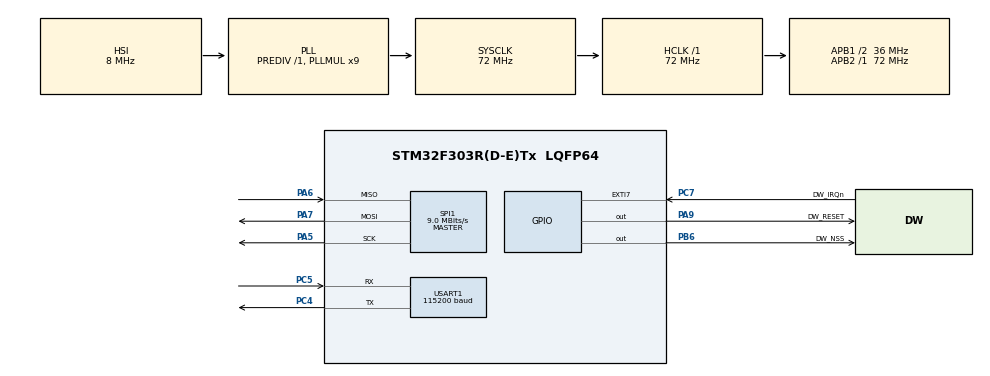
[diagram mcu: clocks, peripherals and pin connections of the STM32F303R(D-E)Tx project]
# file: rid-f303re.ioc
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Mcu.Family=STM32F3
Mcu.Name=STM32F303R(D-E)Tx
Mcu.Package=LQFP64
NVIC.PriorityGroup=NVIC_PRIORITYGROUP_4
PA13.Mode=Serial_Wire
PA13.Signal=SYS_JTMS-SWDIO
PA14.Mode=Serial_Wire
PA14.Signal=SYS_JTCK-SWCLK
PA5.Mode=Full_Duplex_Master
PA5.Signal=SPI1_SCK
PA6.Mode=Full_Duplex_Master
PA6.Signal=SPI1_MISO
PA7.Mode=Full_Duplex_Master
PA7.Signal=SPI1_MOSI
PA9.GPIO_Label=DW_RESET
PA9.Signal=GPIO_Output
PB6.GPIO_Label=DW_NSS
PB6.PinState=GPIO_PIN_SET
PB6.Signal=GPIO_Output
PC4.Mode=Asynchronous
PC4.Signal=USART1_TX
PC5.Mode=Asynchronous
PC5.Signal=USART1_RX
PC7.GPIO_Label=DW_IRQn
PC7.GPIO_PuPd=GPIO_PULLDOWN
PC7.Signal=GPXTI7
ProjectManager.HeapSize=0x200
ProjectManager.StackSize=0x400
ProjectManager.TargetToolchain=STM32CubeIDE
RCC.AHBFreq_Value=72000000
RCC.APB1CLKDivider=RCC_HCLK_DIV2
RCC.APB1Freq_Value=36000000
RCC.APB1TimFreq_Value=72000000
RCC.APB2Freq_Value=72000000
RCC.APB2TimFreq_Value=72000000
RCC.CortexFreq_Value=72000000
RCC.HCLKFreq_Value=72000000
RCC.HSE_VALUE=8000000
RCC.HSI_VALUE=8000000
RCC.LSE_VALUE=32768
RCC.PLLMUL=RCC_PLL_MUL9
RCC.SYSCLKFreq_VALUE=72000000
RCC.SYSCLKSourceVirtual=RCC_SYSCLKSOURCE_PLLCLK
RCC.USBFreq_Value=72000000
SPI1.BaudRatePrescaler=SPI_BAUDRATEPRESCALER_8
SPI1.CalculateBaudRate=9.0 MBits/s
SPI1.DataSize=SPI_DATASIZE_8BIT
SPI1.Direction=SPI_DIRECTION_2LINES
SPI1.Mode=SPI_MODE_MASTER
SPI1.NSSPMode=SPI_NSS_PULSE_DISABLE
SPI1.VirtualType=VM_MASTER
USART1.BaudRate=115200
USART1.VirtualMode-Asynchronous=VM_ASYNC
board=custom

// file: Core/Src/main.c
/* USER CODE BEGIN Header */
/**
  ******************************************************************************
  * @file           : main.c
  * @brief          : Main program body
  ******************************************************************************
  * @attention
  *
  * Copyright (c) 2022 STMicroelectronics.
  * All rights reserved.
  *
  * This software is licensed under terms that can be found in the LICENSE file
  * in the root directory of this software component.
  * If no LICENSE file comes with this software, it is provided AS-IS.
  *
  ******************************************************************************
  */
/* USER CODE END Header */
#include "main.h"

/* USER CODE BEGIN Includes */
#include "stdio_d.h"
#include "rid.h"

//#include "ex_01a_simple_tx/ex_01a_main.c"
/* USER CODE END Includes */

SPI_HandleTypeDef hspi1;

UART_HandleTypeDef huart1;

void SystemClock_Config(void);
static void MX_GPIO_Init(void);
static void MX_SPI1_Init(void);
static void MX_USART1_UART_Init(void);

int main(void)
{

  /* MCU Configuration--------------------------------------------------------*/

  /* Reset of all peripherals, Initializes the Flash interface and the Systick. */
  HAL_Init();

  /* Configure the system clock */
  SystemClock_Config();

  /* Initialize all configured peripherals */
  MX_GPIO_Init();
  MX_SPI1_Init();
  MX_USART1_UART_Init();
  /* USER CODE BEGIN 2 */
  stdio_init(&huart1);
  rid_main();
  //  dw_main();
  /* USER CODE END 2 */

  /* Infinite loop */
  while (1)
  {

  }
}

void SystemClock_Config(void)
{
  RCC_OscInitTypeDef RCC_OscInitStruct = {0};
  RCC_ClkInitTypeDef RCC_ClkInitStruct = {0};
  RCC_PeriphCLKInitTypeDef PeriphClkInit = {0};

  /** Initializes the RCC Oscillators according to the specified parameters
  * in the RCC_OscInitTypeDef structure.
  */
  RCC_OscInitStruct.OscillatorType = RCC_OSCILLATORTYPE_HSI;
  RCC_OscInitStruct.HSIState = RCC_HSI_ON;
  RCC_OscInitStruct.HSICalibrationValue = RCC_HSICALIBRATION_DEFAULT;
  RCC_OscInitStruct.PLL.PLLState = RCC_PLL_ON;
  RCC_OscInitStruct.PLL.PLLSource = RCC_PLLSOURCE_HSI;
  RCC_OscInitStruct.PLL.PLLMUL = RCC_PLL_MUL9;
  RCC_OscInitStruct.PLL.PREDIV = RCC_PREDIV_DIV1;
  if (HAL_RCC_OscConfig(&RCC_OscInitStruct) != HAL_OK)
  {
    Error_Handler();
  }

  /** Initializes the CPU, AHB and APB buses clocks
  */
  RCC_ClkInitStruct.ClockType = RCC_CLOCKTYPE_HCLK|RCC_CLOCKTYPE_SYSCLK
                              |RCC_CLOCKTYPE_PCLK1|RCC_CLOCKTYPE_PCLK2;
  RCC_ClkInitStruct.SYSCLKSource = RCC_SYSCLKSOURCE_PLLCLK;
  RCC_ClkInitStruct.AHBCLKDivider = RCC_SYSCLK_DIV1;
  RCC_ClkInitStruct.APB1CLKDivider = RCC_HCLK_DIV2;
  RCC_ClkInitStruct.APB2CLKDivider = RCC_HCLK_DIV1;

  if (HAL_RCC_ClockConfig(&RCC_ClkInitStruct, FLASH_LATENCY_2) != HAL_OK)
  {
    Error_Handler();
  }
  PeriphClkInit.PeriphClockSelection = RCC_PERIPHCLK_USART1;
  PeriphClkInit.Usart1ClockSelection = RCC_USART1CLKSOURCE_PCLK2;
  if (HAL_RCCEx_PeriphCLKConfig(&PeriphClkInit) != HAL_OK)
  {
    Error_Handler();
  }
}

static void MX_SPI1_Init(void)
{

  /* SPI1 parameter configuration*/
  hspi1.Instance = SPI1;
  hspi1.Init.Mode = SPI_MODE_MASTER;
  hspi1.Init.Direction = SPI_DIRECTION_2LINES;
  hspi1.Init.DataSize = SPI_DATASIZE_8BIT;
  hspi1.Init.CLKPolarity = SPI_POLARITY_LOW;
  hspi1.Init.CLKPhase = SPI_PHASE_1EDGE;
  hspi1.Init.NSS = SPI_NSS_SOFT;
  hspi1.Init.BaudRatePrescaler = SPI_BAUDRATEPRESCALER_8;
  hspi1.Init.FirstBit = SPI_FIRSTBIT_MSB;
  hspi1.Init.TIMode = SPI_TIMODE_DISABLE;
  hspi1.Init.CRCCalculation = SPI_CRCCALCULATION_DISABLE;
  hspi1.Init.CRCPolynomial = 7;
  hspi1.Init.CRCLength = SPI_CRC_LENGTH_DATASIZE;
  hspi1.Init.NSSPMode = SPI_NSS_PULSE_DISABLE;
  if (HAL_SPI_Init(&hspi1) != HAL_OK)
  {
    Error_Handler();
  }

}

static void MX_USART1_UART_Init(void)
{

  huart1.Instance = USART1;
  huart1.Init.BaudRate = 115200;
  huart1.Init.WordLength = UART_WORDLENGTH_8B;
  huart1.Init.StopBits = UART_STOPBITS_1;
  huart1.Init.Parity = UART_PARITY_NONE;
  huart1.Init.Mode = UART_MODE_TX_RX;
  huart1.Init.HwFlowCtl = UART_HWCONTROL_NONE;
  huart1.Init.OverSampling = UART_OVERSAMPLING_16;
  huart1.Init.OneBitSampling = UART_ONE_BIT_SAMPLE_DISABLE;
  huart1.AdvancedInit.AdvFeatureInit = UART_ADVFEATURE_NO_INIT;
  if (HAL_UART_Init(&huart1) != HAL_OK)
  {
    Error_Handler();
  }

}

static void MX_GPIO_Init(void)
{
  GPIO_InitTypeDef GPIO_InitStruct = {0};

  /* GPIO Ports Clock Enable */
  __HAL_RCC_GPIOA_CLK_ENABLE();
  __HAL_RCC_GPIOC_CLK_ENABLE();
  __HAL_RCC_GPIOB_CLK_ENABLE();

  /*Configure GPIO pin Output Level */
  HAL_GPIO_WritePin(GPIOA, GPIO_PIN_9, GPIO_PIN_RESET);

  /*Configure GPIO pin Output Level */
  HAL_GPIO_WritePin(GPIOB, GPIO_PIN_6, GPIO_PIN_SET);

  /*Configure GPIO pin : PC7 */
  GPIO_InitStruct.Pin = GPIO_PIN_7;
  GPIO_InitStruct.Mode = GPIO_MODE_IT_RISING;
  GPIO_InitStruct.Pull = GPIO_PULLDOWN;
  HAL_GPIO_Init(GPIOC, &GPIO_InitStruct);

  /*Configure GPIO pin : PA9 */
  GPIO_InitStruct.Pin = GPIO_PIN_9;
  GPIO_InitStruct.Mode = GPIO_MODE_OUTPUT_PP;
  GPIO_InitStruct.Pull = GPIO_NOPULL;
  GPIO_InitStruct.Speed = GPIO_SPEED_FREQ_LOW;
  HAL_GPIO_Init(GPIOA, &GPIO_InitStruct);

  /*Configure GPIO pin : PB6 */
  GPIO_InitStruct.Pin = GPIO_PIN_6;
  GPIO_InitStruct.Mode = GPIO_MODE_OUTPUT_PP;
  GPIO_InitStruct.Pull = GPIO_NOPULL;
  GPIO_InitStruct.Speed = GPIO_SPEED_FREQ_LOW;
  HAL_GPIO_Init(GPIOB, &GPIO_InitStruct);

}

void Error_Handler(void)
{
  __disable_irq();
  while (1)
  {
  }
}
